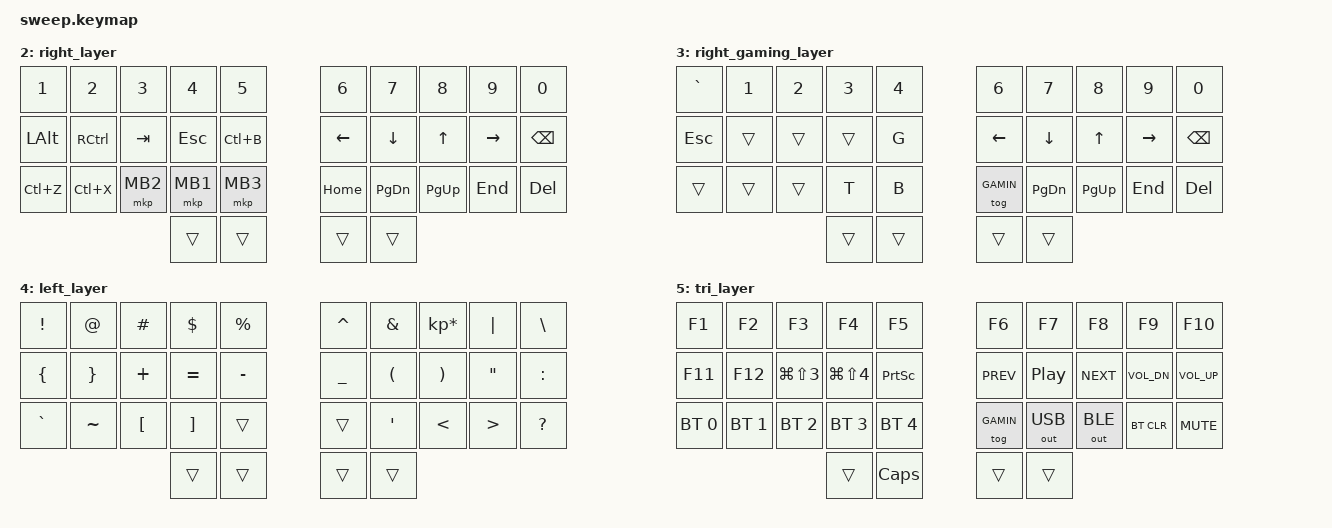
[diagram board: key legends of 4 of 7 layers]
// Copyright (c) 2022 The ZMK Contributors
// SPDX-License-Identifier: MIT

#include <behaviors.dtsi>
#include <dt-bindings/zmk/keys.h>
#include <dt-bindings/zmk/bt.h>
#include <dt-bindings/zmk/outputs.h>
#include <dt-bindings/zmk/mouse.h>

#define DEFAU 0
#define GAMIN 1
#define LOWER 2
#define LOWEG 3
#define RAISE 4
#define SUPER 5
#define TILIN 6
#define HRML(k1,k2,k3,k4) &lt TILIN k1  &hm LCTRL k2  &hm LALT k3  &hm LGUI k4
#define HRMR(k1,k2,k3,k4) &hm LGUI k1  &hm RALT  k2 &hm RCTRL k3  &lt TILIN k4

/ {

    conditional_layers {
        compatible = "zmk,conditional-layers";
        tri_layer {
            if-layers = <LOWER RAISE>;
            then-layer = <SUPER>;
        };
        tri_layer_gaming {
            if-layers = <LOWEG RAISE>;
            then-layer = <SUPER>;
        };
    };
    behaviors {
        hm: homerow_mods {
            compatible = "zmk,behavior-hold-tap";
            label = "HOMEROW_MODS";
            #binding-cells = <2>;
            tapping-term-ms = <200>;
            quick-tap-ms = <0>;
            flavor = "tap-preferred";
            bindings = <&kp>, <&kp>;
        };

        hk: homerow_hold {
            compatible = "zmk,behavior-hold-tap";
            label = "HOLD_MOD";
            #binding-cells = <2>;
            tapping-term-ms = <150>;
            quick-tap-ms = <0>;
            flavor = "balanced";
            bindings = <&kp>, <&kp>;
        };

        hs: hold_custom {
            compatible = "zmk,behavior-hold-tap";
            label = "HOLD_CUSTOM";
            #binding-cells = <2>;
            tapping-term-ms = <500>;
            quick-tap-ms = <0>;
            flavor = "tap-preferred";
            bindings = <&kp>, <&kp>;
        };

    };


    keymap {
        compatible = "zmk,keymap";
        default_layer {
            bindings = <
            &kp Q      &kp W      &kp E      &kp R      &kp T          &kp Y      &kp U      &kp I      &kp O      &kp P
            HRML(A,        S,         D,         F)     &kp G          &kp H      HRMR(J,        K,         L,        SEMI)
            &kp Z      &kp X      &kp C      &kp V      &kp B          &kp N      &kp M      &kp COMMA  &kp DOT    &kp FSLH
                                            &mo LOWER &hm LSHFT SPACE   &hk LSHFT RET &mo RAISE            
            >;
        };

        gaming_layer {
            bindings = <
            &kp TAB   &kp Q       &kp W      &kp E &kp R        &kp Y      &kp U      &kp I      &kp O      &kp P
            &kp LCTRL &kp A       &kp S      &kp D &kp F        &kp H      HRMR(J,        K,         L,        SEMI)
            &kp LSHFT &kp Z       &kp X      &kp C &kp V        &kp N      &kp M      &kp COMMA  &kp DOT    &kp FSLH
                                            &mo LOWEG &kp SPACE   &tog GAMIN &mo RAISE            
            >;
        };

        right_layer {
            bindings = <
               &kp N1       &kp N2       &kp N3       &kp N4       &kp N5         &kp N6   &kp N7    &kp N8    &kp N9    &kp N0   
               &kp LALT     &kp RCTRL    &kp TAB      &kp ESC      &kp LC(B)      &kp LEFT &kp DOWN  &kp UP    &kp RIGHT &kp BSPC  
               &kp LC(Z)    &kp LC(X)    &mkp MB2      &mkp MB1    &mkp MB3         &kp HOME &kp PG_DN &kp PG_UP &kp END   &kp DEL  
                          	        &trans       &trans       &trans  &trans    
            >;
        };

        right_gaming_layer {
            bindings = <
                 &kp GRAVE  &kp N1       &kp N2       &kp N3       &kp N4            &kp N6   &kp N7    &kp N8    &kp N9    &kp N0   
                 &kp ESC    &trans       &trans       &trans       &kp G             &kp LEFT &kp DOWN  &kp UP    &kp RIGHT &kp BSPC  
                 &trans     &trans       &trans       &kp T        &kp B             &tog GAMIN &kp PG_DN &kp PG_UP &kp END   &kp DEL  
                                                &trans       &trans       &trans  &trans    
            >;
        };


        left_layer {
            bindings = <
   &kp EXCL  &kp AT    &kp HASH &kp DLLR    &kp PRCNT   &kp CARET &kp AMPS  &kp KP_MULTIPLY &kp PIPE  &kp BSLH  
   &kp LBRC  &kp RBRC  &kp PLUS &kp EQUAL   &kp MINUS   &kp UNDER &kp LPAR  &kp RPAR        &kp DQT   &kp COLON 
   &kp GRAVE &kp TILDE &kp LBKT &kp RBKT    &trans      &trans    &kp SQT   &kp LT          &kp GT    &kp QMARK   
                    	       &trans   &trans       &trans      &trans    
            >;
        };

        tri_layer {
            bindings = <
     &kp F1       &kp F2       &kp F3        &kp F4        &kp F5         &kp F6     &kp F7     &kp F8     &kp F9       &kp F10      
     &kp F11         &kp F12          &kp LG(LS(N3)) &kp LG(LS(N4)) &kp PSCRN      &kp C_PREV &kp C_PP   &kp C_NEXT &kp C_VOL_DN &kp C_VOL_UP 
     &bt BT_SEL 0 &bt BT_SEL 1 &bt BT_SEL 2  &bt BT_SEL 3  &bt BT_SEL 4   &tog GAMIN     &out OUT_USB       &out OUT_BLE   &bt BT_CLR    &kp C_MUTE       
                          	        &trans        &kp CAPS       &trans         &trans     
            >;
        };


        tiling_layer {
                bindings = <
      &hs LC(LA(LS(N1))) LA(LS(N1)) &hs LC(LA(LS(N2))) LA(LS(N2))  &hs LC(LA(LS(N3))) LA(LS(N3)) &hs LC(LA(LS(N4))) LA(LS(N4)) &hs LC(LA(LS(N5))) LA(LS(N5)) &hs LC(LA(LS(N6))) LA(LS(N6)) &hs LC(LA(LS(N7))) LA(LS(N7)) &hs LC(LA(LS(N8))) LA(LS(N8)) &hs LC(LA(LS(N9))) LA(LS(N9)) &trans      
      &trans         &kp LA(LS(W))   &hs LC(LA(LS(E))) LA(LS(E))  &hs LC(LA(LS(R))) LA(LS(R))    &hs LC(LA(LS(T))) LA(LS(T))         &trans     &trans     &trans     &trans       &trans      
      &kp LA(LS(A))  &kp LA(LS(S))   &kp LA(LS(D))  &trans        &trans         &trans     &trans     &trans     &trans       &trans      
                                        &trans       &kp LG(SPACE)         &trans     &trans     
                >;
        };

    };
};
